# AE101F4071542LH_CM55_HE_View register map
Vendor: Alif Semiconductor; Series: E1; File version: 1.0
CPU: CM55 r1p0, selectable endian, MPU, FPU, double-precision FPU, DSP, VTOR, 8 interrupt priority bits, 1 SAU regions
Registers are 32-bit, read-write, reset 0x0 unless marked. A register's access mark holds for its fields unless they carry their own. Offsets are from the block's base; [hi:lo] are bit positions; {n}, {i} and the like mark numbered series; 'fields as' and 'values as' point back to an identical list.

## LPI2C
Base 0x43009000
0x00 LPI2C_DATA — Read/Write Data Register
  [7:0] DATA — If the corresponding FIFO is not empty/full, a byte of data can be read/written to this address. From FIFO's perspective, it would be like a pop/push operation.
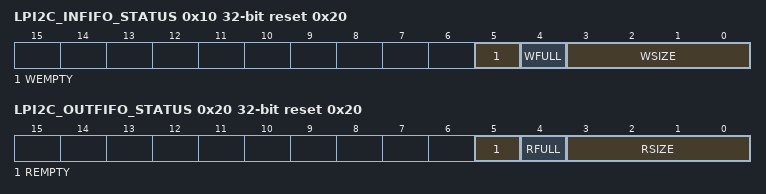
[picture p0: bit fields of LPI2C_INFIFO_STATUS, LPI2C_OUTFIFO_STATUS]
0x10 LPI2C_INFIFO_STATUS ro reset 0x20 — Inbound FIFO Status Register
  [5] WEMPTY — This field shows if the inbound FIFO is empty.
    0=Not empty; 1=Empty
  [4] WFULL — This field shows if the inbound FIFO is full.
    0=Not full; 1=Full
  [3:0] WSIZE — This field shows the number of available bytes of data in the inbound FIFO.
0x20 LPI2C_OUTFIFO_STATUS ro reset 0x20 — Outbound FIFO Status Register
  [5] REMPTY — This field shows if the outbound FIFO is empty.
    0=Not empty; 1=Empty
  [4] RFULL — This field shows if the outbound FIFO is full.
    0=Not full; 1=Full
  [3:0] RSIZE — This field shows the number of bytes of data in the outbound FIFO to be transmitted.

## CRC0
Base 0x48107000
Same registers: CRC1 0x48108000
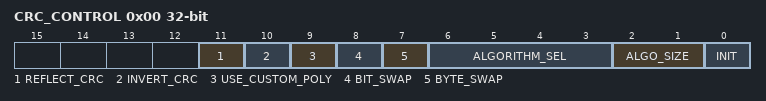
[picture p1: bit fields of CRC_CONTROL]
0x00 CRC_CONTROL — CRC Calculation Setup Register
  [11] REFLECT_CRC — Reflection of the CRC result as it is read out. An 8-bit CRC value is reflected on [7-0], bit7 to bit0, bit6 to bit1, etc. 16-bit and 32-bit CRC are reflected similarly.
    0=Reflection is disabled; 1=Reflection is enabled
  [10] INVERT_CRC — Inverting of each bit of the calculated CRC as it is read out.
    0=The CRC is not inverted; 1=Each bit is inverted
  [9] USE_CUSTOM_POLY — Use of a custom polynomial for CRC calculations. Note: Custom polynomials can only be used for 32-bit CRC algorithms.
    0=Custom polynomial is not used. The algorithm selected in CRC_CONTROL[ALGORITHM_SEL] bit field is used for the CRC calculation.; 1=Enable the use of a custom polynomial. For more information of the supported polynomials and their format, see Section CRC Overview and Section CRC Polynomials.
  [8] BIT_SWAP — Bit swapping during CRC calculation.
    0=Do not swap bits; 1=Swap the bits within each byte
  [7] BYTE_SWAP — Byte swapping during CRC calculation.
    0=Do not swap bytes; 1=Swap the bytes within each word (16-bit and 32-bit calculations only)
  [6:3] ALGORITHM_SEL — Algorithm selection.
    0=CRC-8-CCITT; 2=CRC-16; 3=CRC-16-CCITT; 4=CRC-32; 5=CRC-32C
  [2:1] ALGO_SIZE — Algorithm size selection. Must program CRC_CONTROL[ALGO_SIZE] = 0x2 when using custom polynomials.
    0=8-bit; 1=16-bit; 2=32-bit
  [0] INIT — Writing INIT will load seed and polynomial. Reading will always return INIT = 0. Bit must always be written to 0x1 before starting CRC calculations.
0x10 CRC_SEED reset 0xFFFFFFFF — Seed Value Register
  [31:0] SEED — Seed value.
0x14 CRC_POLY_CUSTOM — Custom Polynomial Register
  [31:0] CRC_POLY_CUSTOM — Bits 31-0 are used for custom 32-bit CRC calculations.
0x18 CRC_OUT ro — Accumulated CRC Register
  [31:0] CRC_OUT — Bits 31-0 are used for reading out 32-bit CRC calculations. Bits 15-0 are used for reading out 16-bit CRCs. Lowest eight bits 7-0 are used for reading out 8-bit CRCs.
{0x20+i} CRC_DATA_IN_8_[{i}] (i=0..63) 8-bit wo reset not defined — 8-bit Values Register n
  [7:0] CRC_DATA_IN_8 — Data written in this register is for 8-bit and 16-bit calculations, but only 8-bits can be written per beat.
{0x60+4i} CRC_DATA_IN_32_[{i}] (i=0..39) wo reset not defined — 32-bit Values Register n
  [31:0] CRC_DATA_IN_32 — Data written in this register is for 32-bit calculations.

## CMP0
Base 0x49023000
Same registers: CMP1 0x49024000
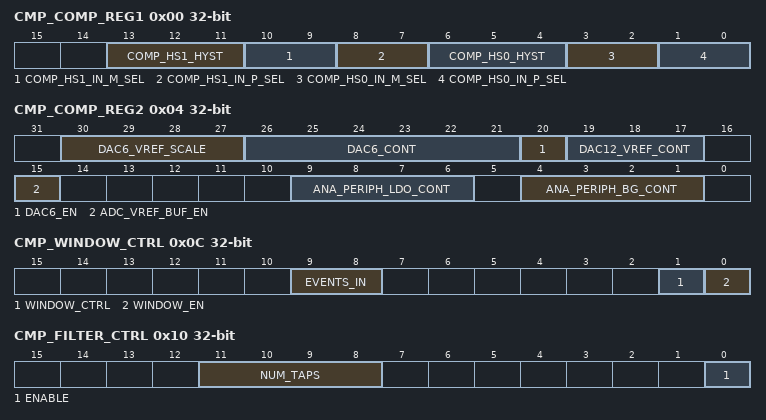
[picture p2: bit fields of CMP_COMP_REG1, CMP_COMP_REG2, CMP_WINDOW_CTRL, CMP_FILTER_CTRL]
0x00 CMP_COMP_REG1 — CMP Control Register 1
  [13:11] COMP_HS1_HYST — Sets CMP1 hysteresis level. 6-mV steps.
    0=0 mV; 7=45 mV
  [10:9] COMP_HS1_IN_M_SEL — Selects input to negative terminal of CMP1:
    0=VREF_IN0 pin; 1=VREF_IN1 pin; 2=Internal Vref; 3=DAC6
  [8:7] COMP_HS1_IN_P_SEL — Selects input to positive terminal of CMP1:
    {v}=CMP1_IN{v} pin (v=0..3)
  [6:4] COMP_HS0_HYST — Sets CMP0 hysteresis level. 6-mV steps.
    0=0 mV; 7=45 mV
  [3:2] COMP_HS0_IN_M_SEL — Selects input to negative terminal of CMP0:
    0=VREF_IN0 pin; 1=VREF_IN1 pin; 2=Internal Vref; 3=DAC6
  [1:0] COMP_HS0_IN_P_SEL — Selects input to positive terminal of CMP0:
    {v}=CMP0_IN{v} pin (v=0..3)
0x04 CMP_COMP_REG2 — CMP Control Register 2
  [30:27] DAC6_VREF_SCALE — Allows you to scale the input reference to the DAC6. Step Size = 1/16
    0=1x; 15=2x
  [26:21] DAC6_CONT — This is the output of DAC6 programmable reference voltage. DAC6 Output = (DAC6_VREF_SCALE x DAC6_CONT) / 64
  [20] DAC6_EN — DAC6 Enable. DAC6 takes an input reference and generates a 6-bit programmable output voltage reference.
  [19:17] DAC12_VREF_CONT — Voltage reference values for DAC12
    0=Val_0b000 (0.500 V); 1=Val_0b001 (0.667 V); 2=Val_0b010 (0.667 V); 3=Val_0b011 (0.750 V); 4=Val_0b100 (0.750 V (Default)); 5=Val_0b101 (0.800 V); 6=Val_0b110 (0.800 V); 7=Val_0b111 (0.833 V)
  [15] ADC_VREF_BUF_EN — ADC Vref buffer enable. Turn off if external VREF is connected.
    0=ADC Vref is off; 1=ADC Vref is on
  [9:6] ANA_PERIPH_LDO_CONT — Analog peripheral LDO (LDO-5) output voltage (VDD_ANA): Step: 20 mV
    0=Val_0b0000 (1.6 V); 15=Val_0b1111 (1.9 V); 10=Val_0b1010 (1.8 V = Default (0xA))
  [4:1] ANA_PERIPH_BG_CONT — Calibration for analog peripherals precision bandgap (desired 1.2 V): Step: 6 mV
    0=Val_0b0000 (1.140 V); 15=Val_0b1111 (1.233 V); 10=Val_0b1010 (1.200 V = Default (0xA))
0x08 CMP_POLARITY_CTRL — CMP Polarity Control Register
  [0] POLARITY_CTRL — If = 0x1, invert the value of CMP_OUT (comparison result) before processing.
0x0C CMP_WINDOW_CTRL — CMP Window Control Register
  [9:8] EVENTS_IN — Selects which of the 4 inputs will control the processing window.
  [1] WINDOW_CTRL — Window function control bit. Note: Bits WINDOW_CTRL and WINDOW_EN must be both set to use windowing function.
    0=Continuously process comparator inputs; 1=Use the EVENTS_IN bit field setting. Selected input will control when to look at comparator inputs.
  [0] WINDOW_EN — Window function enable bit. Note: Bits WINDOW_CTRL and WINDOW_EN must be both set to use windowing function.
    values as WINDOW_CTRL
0x10 CMP_FILTER_CTRL — CMP Filter Control Register
  [11:8] NUM_TAPS — Number of filter taps, 2-8 taps.
  [0] ENABLE — Filtering function enable bit.
0x14 CMP_PRESCALER_CTRL — CMP Prescaler Control Register
  [5:0] PRESCALER_CTRL — Number of clocks between updating taps with new comparator input.
0x20 CMP_INTERRUPT_STATUS wo — CMP Interrupt Status and Clear Register
  [0] FILTER_EVENT write-1-clears — FILTER_EVENT interrupt status and clear. When read as 1: Filter event occurred for the programmed number of taps. Write 1 to clear.
0x24 CMP_INTERRUPT_MASK reset 0x1
  [0] FILTER_EVENT — Mask for the FILTER_EVENT interrupt. Note: By default, interrupt mask is set. Mask must be cleared to allow interrupt to be driven out.
    0=Clear mask; 1=Set mask
